# FE310 register map
Vendor: SiFive
Registers are 32-bit, read-write, reset 0x0 unless marked. A register's access mark holds for its fields unless they carry their own. Offsets are from the block's base; [hi:lo] are bit positions; {n}, {i} and the like mark numbered series; 'fields as' and 'values as' point back to an identical list.

## OTP — One Time Programmable Memory
Base 0x10010000
0x00 lock — Programmed-I/O lock register
0x04 clock — OTP device clock signal
0x08 output_en — OTP device output-enable signal
0x0C select — OTP device chip-select signal
0x10 write_en — OTP device write-enable signal
0x14 mode — OTP device mode register
0x18 mrr — OTP read-voltage regulator control
0x1C mpp — OTP write-voltage charge pump control
0x20 vrren — OTP read-voltage enable
0x24 vppen — OTP write-voltage enable
0x28 addr — OTP device address
0x2C data_in — OTP device data input
0x30 data_out — OTP device data output
0x34 rsctrl — OTP read sequencer control

## GPIO0 — General Purpose Input Output
Base 0x10012000
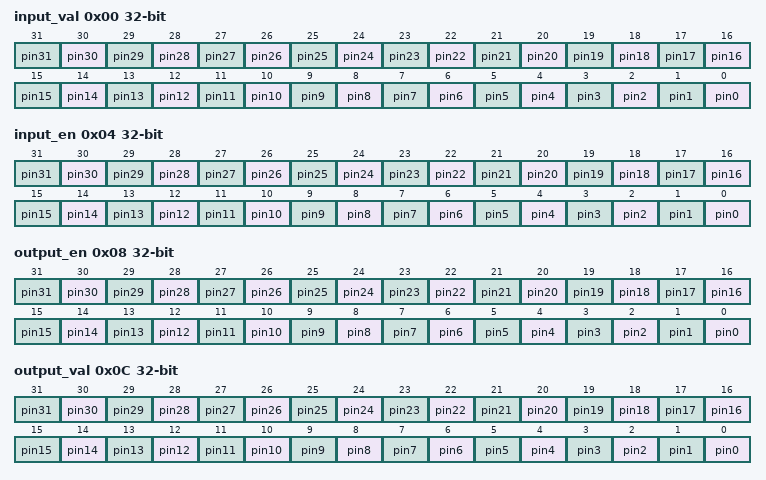
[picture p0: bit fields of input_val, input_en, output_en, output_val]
0x00 input_val — Pin value.
  [n] pin{n} (n=0..31)
0x04 input_en — Pin Input Enable Register
  [n] pin{n} (n=0..31)
0x08 output_en — Pin Output Enable Register
  [n] pin{n} (n=0..31)
0x0C output_val — Output Port Value Register
  [n] pin{n} (n=0..31)
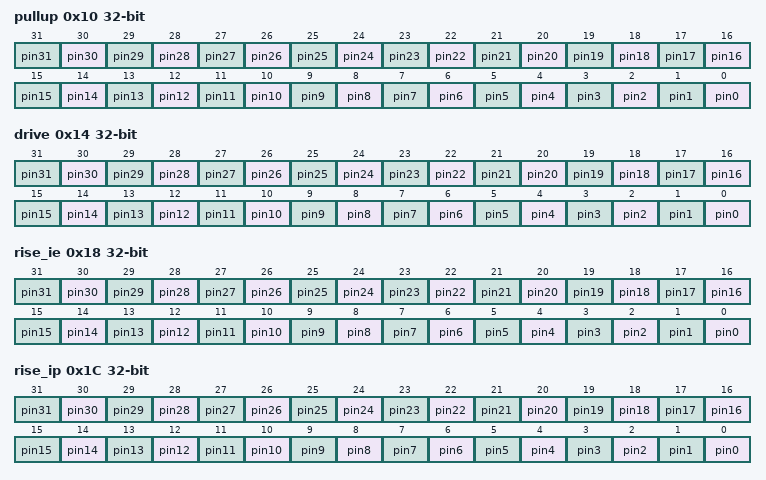
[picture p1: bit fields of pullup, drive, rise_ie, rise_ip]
0x10 pullup — Internal Pull-Up Enable Register
  [n] pin{n} (n=0..31)
0x14 drive — Drive Strength Register
  [n] pin{n} (n=0..31)
0x18 rise_ie — Rise Interrupt Enable Register
  [n] pin{n} (n=0..31)
0x1C rise_ip — Rise Interrupt Pending Register
  [n] pin{n} (n=0..31)
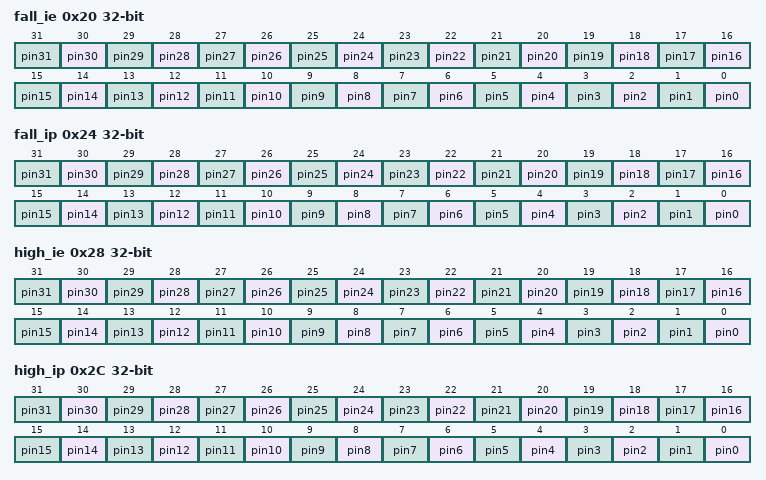
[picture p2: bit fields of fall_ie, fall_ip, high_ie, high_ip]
0x20 fall_ie — Fall Interrupt Enable Register
  [n] pin{n} (n=0..31)
0x24 fall_ip — Fall Interrupt Pending Register
  [n] pin{n} (n=0..31)
0x28 high_ie — High Interrupt Enable Register
  [n] pin{n} (n=0..31)
0x2C high_ip — High Interrupt Pending Register
  [n] pin{n} (n=0..31)
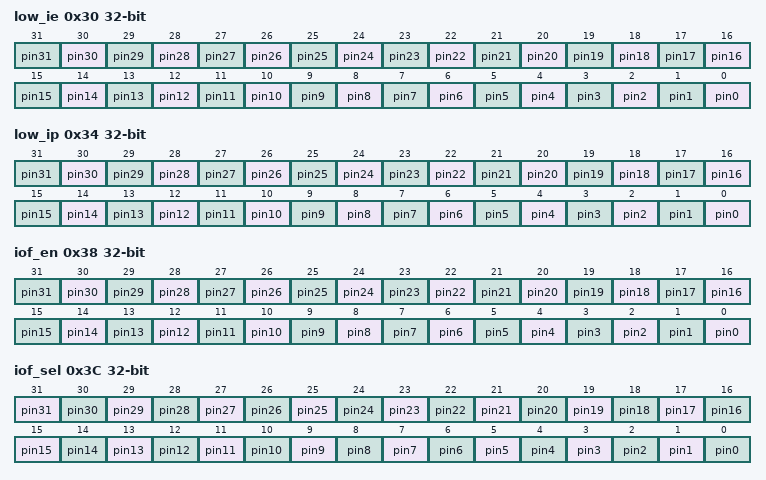
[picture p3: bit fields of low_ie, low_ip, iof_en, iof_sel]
0x30 low_ie — Low Interrupt Enable Register
  [n] pin{n} (n=0..31)
0x34 low_ip — Low Interrupt Pending Register
  [n] pin{n} (n=0..31)
0x38 iof_en — HW I/O Function Enable Register
  [n] pin{n} (n=0..31)
0x3C iof_sel — HW I/O Function Select Register
  [31] pin31
    0=QSPI2_SD3; 1=IOF1
  [30] pin30
    0=QSPI2_SD2; 1=IOF1
  [29] pin29
    0=QSPI2_SCK; 1=IOF1
  [28] pin28
    0=QSPI2_SD1; 1=IOF1
  [27] pin27
    0=QSPI2_SD0; 1=IOF1
  [26] pin26
    0=QSPI2_SS; 1=IOF1
  [25] pin25
    0=UART1_TX; 1=IOF1
  [24] pin24
    0=UART1_RX; 1=IOF1
  [23] pin23
    0=IOF0; 1=IOF1
  [22] pin22
    0=IOF0; 1=PWM1_3
  [21] pin21
    0=IOF0; 1=PWM1_2
  [20] pin20
    0=IOF0; 1=PWM1_0
  [19] pin19
    0=IOF0; 1=PWM1_1
  [18] pin18
    0=IOF0; 1=IOF1
  [17] pin17
    0=UART0_TX; 1=IOF1
  [16] pin16
    0=UART0_RX; 1=IOF1
  [15] pin15
    0=IOF0; 1=IOF1
  [14] pin14
    0=IOF0; 1=IOF1
  [13] pin13
    0=IOF0; 1=PWM2_3
  [12] pin12
    0=IOF0; 1=PWM2_2
  [11] pin11
    0=IOF0; 1=PWM2_1
  [10] pin10
    0=QSPI1_SS3; 1=PWM2_0
  [9] pin9
    0=QSPI1_SS2; 1=IOF1
  [8] pin8
    0=QSPI1_SS1; 1=IOF1
  [7] pin7
    0=QSPI1_SD3; 1=IOF1
  [6] pin6
    0=QSPI1_SD2; 1=IOF1
  [5] pin5
    0=QSPI1_SCK; 1=IOF1
  [4] pin4
    0=QSPI1_SD1; 1=IOF1
  [3] pin3
    0=QSPI1_SD0; 1=PWM0_3
  [2] pin2
    0=QSPI1_SS0; 1=PWM0_2
  [1] pin1
    0=IOF0; 1=PWM0_1
  [0] pin0
    0=IOF0; 1=PWM0_0
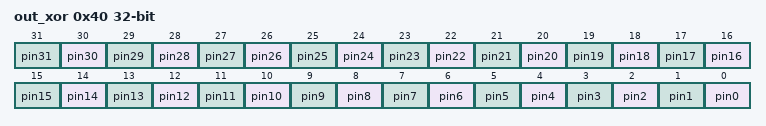
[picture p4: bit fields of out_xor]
0x40 out_xor — Output XOR (invert) Register
  [n] pin{n} (n=0..31)

## UART0 — Universal Asynchronous Receiver Transmitter
Base 0x10013000
Same registers: UART1 0x10023000
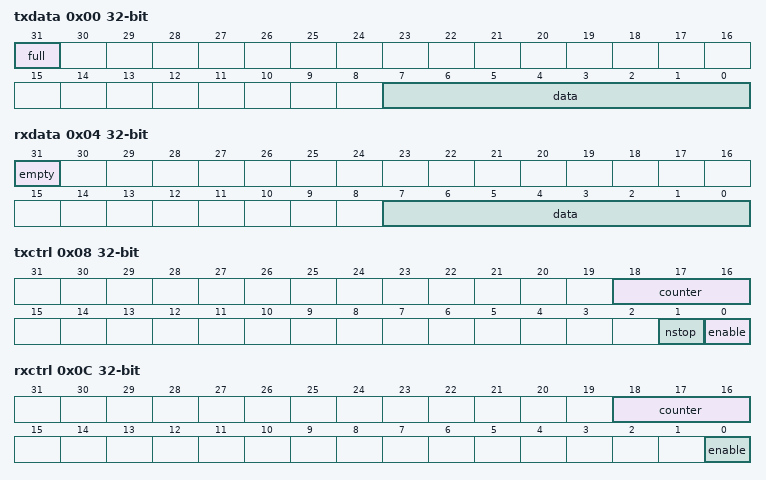
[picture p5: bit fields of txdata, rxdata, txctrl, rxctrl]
0x00 txdata — Transmit Data Register
  [31] full, [7:0] data
0x04 rxdata — Receive Data Register
  [31] empty, [7:0] data
0x08 txctrl — Transmit Control Register
  [18:16] counter, [1] nstop, [0] enable
0x0C rxctrl — Receive Control Register
  [18:16] counter, [0] enable
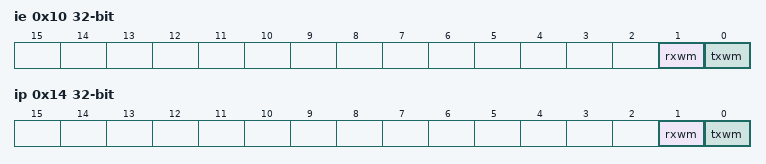
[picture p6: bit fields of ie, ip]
0x10 ie — Interrupt Enable Register
  [1] rxwm, [0] txwm
0x14 ip — Interrupt Pending Register
  [1] rxwm, [0] txwm
0x18 div — Baud Rate Divisor Register
  [15:0] value

## QSPI0 — Quad Serial Peripheral Interface
Base 0x10014000
Same registers: QSPI1 0x10024000, QSPI2 0x10034000
0x00 sckdiv — Serial Clock Divisor Register
  [11:0] div — Divisor for serial clock
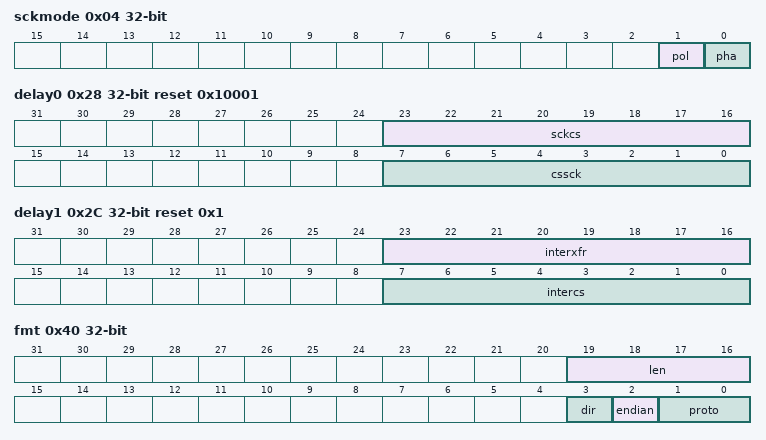
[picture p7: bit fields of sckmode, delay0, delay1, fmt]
0x04 sckmode — Serial Clock Mode Register
  [1] pol — Serial clock polarity
  [0] pha — Serial clock phase
0x10 csid — Chip Select ID Register
0x14 csdef reset 0xFFFF — Chip Select Default Register
0x18 csmode — Chip Select Mode Register
  [1:0] mode — Chip select mode
    0=Auto (Assert/de-assert CS at the beginning/end of each frame.); 2=Hold (Keep CS continuously asserted after the initial frame.); 3=Off (Disable hardware control of the CS pin.)
0x28 delay0 reset 0x10001 — Delay Control 0 Register
  [23:16] sckcs — SCK to CS Delay
  [7:0] cssck — CS to SCK Delay
0x2C delay1 reset 0x1 — Delay Control 1 Register
  [23:16] interxfr — Maximum interframe delay
  [7:0] intercs — Minimum CS inactive time
0x40 fmt — Frame Format Register
  [19:16] len — Number of bits per frame
  [3] dir — SPI I/O direction
    0=Rx (For dual and quad protocols, the DQ pins are tri-stated. For the single protocol, the DQ0 pin is driven with the transmit data as normal.); 1=Tx (The receive FIFO is not populated.)
  [2] endian — SPI endianness
    0=Big (Transmit MSB first.); 1=Little (Transmit LSB first.)
  [1:0] proto — SPI protocol
    0=Single (DQ0 (MOSI), DQ1 (MISO)); 1=Dual (DQ0, DQ1); 2=Quad (DQ0, DQ1, DQ2, DQ3)
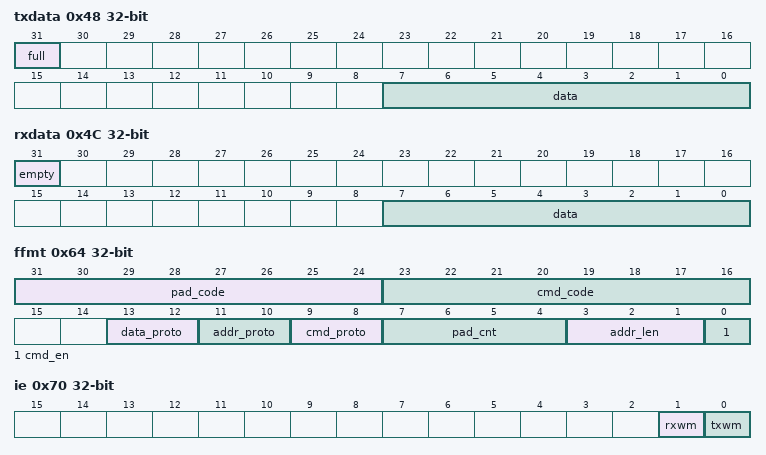
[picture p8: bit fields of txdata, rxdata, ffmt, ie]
0x48 txdata — Transmit Data Register
  [31] full — FIFO full flag
  [7:0] data — Transmit data
0x4C rxdata — Receive Data Register
  [31] empty — FIFO empty flag
  [7:0] data — Received data
0x50 txmark — Transmit Watermark Register
  [2:0] txmark — Transmit watermark
0x54 rxmark — Receive Watermark Register
  [2:0] rxmark — Receive watermark
0x60 fctrl — SPI Flash Interface Control Register
  [0] en — SPI Flash Mode Select
0x64 ffmt — SPI Flash Instruction Format Register
  [31:24] pad_code — First 8 bits to transmit during dummy cycles
  [23:16] cmd_code — Value of command byte
  [13:12] data_proto — Protocol for receiving data bytes
    values as fmt.proto
  [11:10] addr_proto — Protocol for transmitting address and padding
    values as fmt.proto
  [9:8] cmd_proto — Protocol for transmitting command
    values as fmt.proto
  [7:4] pad_cnt — Number of dummy cycles
  [3:1] addr_len — Number of address bytes (0 to 4)
  [0] cmd_en — Enable sending of command
0x70 ie — SPI Interrupt Enable Register
  [1] rxwm — Receive watermark enable
  [0] txwm — Transmit watermark enable
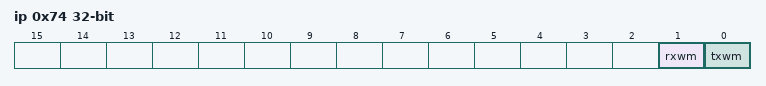
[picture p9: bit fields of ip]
0x74 ip — SPI Interrupt Pending Register
  fields as ie

## PWM0 — 8-bit timer with 4 cmp
Base 0x10015000
Same registers: PWM1 0x10025000, PWM2 0x10035000
0x00 cfg — PWM Configuration Register
  [n+28] cmp{n}ip (n=0..3), [27] cmp3gang, [36:26] cmp2gang, [25] cmp1gang, [24] cmp0gang, [n+16] cmp{n}center (n=0..3), [13] enoneshot, [12] enalways, [10] deglitch, [9] zerocmp, [8] sticky, [3:0] scale
0x08 count — Counter Register
0x10 pwms — Scaled Halfword Counter Register
{0x20+4i} cmp{i} (i=0..3) — Compare Register
  [15:0] value

## I2C0 — Inter-Integrated Circuit Master Interface (FE310-G002 only)
Base 0x10016000
0x00 prer_lo — Clock Prescale register lo-byte
  [7:0] value
0x04 prer_hi — Clock Prescale register hi-byte
  [7:0] value
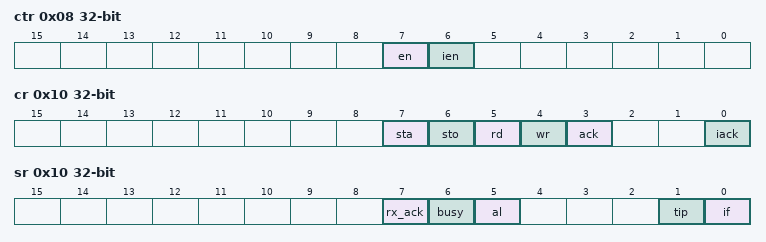
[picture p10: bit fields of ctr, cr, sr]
0x08 ctr — Control register
  [7] en — I2C core enable bit
  [6] ien — I2C core interrupt enable bit
0x0C txr_rxr — Transmit register / Receive register
  [7:0] data
0x10 cr_sr — Command register / Status register
0x10 cr wo — Command register
  [7] sta — Generate (repeated) start condition
  [6] sto — Generate stop condition
  [5] rd — Read from slave
  [4] wr — Write to slave
  [3] ack — When a receiver, sent ACK (0) or NACK (1)
    0=ack; 1=nack
  [0] iack — Interrupt acknowledge. When set, clears a pending interrupt
0x10 sr ro (alternate view of cr) — Status register
  [7] rx_ack — Received acknowledge from slave. This flag represents acknowledge from the addressed slave. '1' = No acknowledge received '0' = Acknowledge received
  [6] busy — I2C bus busy
  [5] al — Arbitration lost
  [1] tip — Transfer in progress
  [0] if — Interrupt Flag. This bit is set when an interrupt is pending, which will cause a processor interrupt request if the IEN bit is set.
